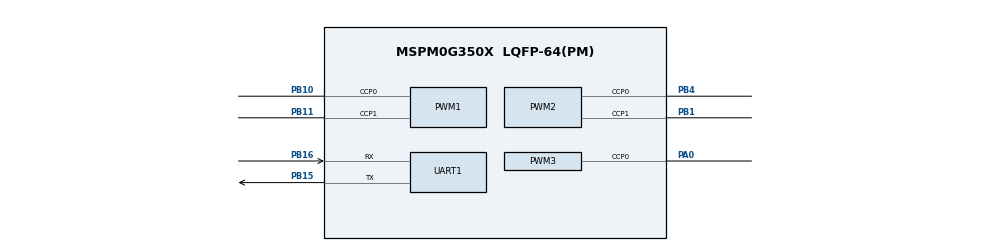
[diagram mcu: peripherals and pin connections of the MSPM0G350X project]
/**
 * @cliArgs --device "MSPM0G350X" --part "Default" --package "LQFP-64(PM)" --product "mspm0_sdk@2.11.00.07"
 * @versions {"tool":"1.26.2+4477"}
 */

/**
 * Import the modules used in this configuration.
 */
const GPIO          = scripting.addModule("/ti/driverlib/GPIO", {}, false);
const GPIO1         = GPIO.addInstance();
const PWM           = scripting.addModule("/ti/driverlib/PWM", {}, false);
const PWM1          = PWM.addInstance();
const PWM2          = PWM.addInstance();
const PWM3          = PWM.addInstance();
const SYSCTL        = scripting.addModule("/ti/driverlib/SYSCTL");
const UART          = scripting.addModule("/ti/driverlib/UART", {}, false);
const UART1         = UART.addInstance();
const ProjectConfig = scripting.addModule("/ti/project_config/ProjectConfig");

/**
 * Write custom configuration values to the imported modules.
 */
GPIO1.$name                          = "GPIO_GRP_0";
GPIO1.associatedPins[0].$name        = "PIN_0";
GPIO1.associatedPins[0].assignedPort = "PORTA";
GPIO1.associatedPins[0].ioStructure  = "SD";
GPIO1.associatedPins[0].assignedPin  = "2";

const Board = scripting.addModule("/ti/driverlib/Board", {}, false);

PWM1.$name                      = "PWM_0";
PWM1.peripheral.ccp0Pin.$assign = "PB10";
PWM1.peripheral.ccp1Pin.$assign = "PB11";
PWM1.PWM_CHANNEL_0.$name        = "ti_driverlib_pwm_PWMTimerCC0";
PWM1.PWM_CHANNEL_1.$name        = "ti_driverlib_pwm_PWMTimerCC1";
PWM1.ccp0PinConfig.$name        = "ti_driverlib_gpio_GPIOPinGeneric0";
PWM1.ccp1PinConfig.$name        = "ti_driverlib_gpio_GPIOPinGeneric1";

PWM2.$name                      = "PWM_1";
PWM2.peripheral.$assign         = "TIMA1";
PWM2.peripheral.ccp0Pin.$assign = "PB4";
PWM2.peripheral.ccp1Pin.$assign = "PB1";
PWM2.PWM_CHANNEL_0.$name        = "ti_driverlib_pwm_PWMTimerCC2";
PWM2.PWM_CHANNEL_1.$name        = "ti_driverlib_pwm_PWMTimerCC3";
PWM2.ccp0PinConfig.$name        = "ti_driverlib_gpio_GPIOPinGeneric2";
PWM2.ccp1PinConfig.$name        = "ti_driverlib_gpio_GPIOPinGeneric3";

PWM3.$name                      = "PWM_2";
PWM3.peripheral.ccp0Pin.$assign = "PA0";
PWM3.PWM_CHANNEL_0.$name        = "ti_driverlib_pwm_PWMTimerCC4";
PWM3.PWM_CHANNEL_1.$name        = "ti_driverlib_pwm_PWMTimerCC5";
PWM3.ccp0PinConfig.$name        = "ti_driverlib_gpio_GPIOPinGeneric6";
PWM3.ccp1PinConfig.$name        = "ti_driverlib_gpio_GPIOPinGeneric7";


UART1.$name                            = "UART_2";
UART1.targetBaudRate                   = 115200;
UART1.peripheral.$assign               = "UART2";
UART1.peripheral.rxPin.$assign         = "PB16";
UART1.peripheral.txPin.$assign         = "PB15";
UART1.txPinConfig.$name                = "ti_driverlib_gpio_GPIOPinGeneric4";
UART1.txPinConfig.direction            = scripting.forceWrite("OUTPUT");
UART1.txPinConfig.hideOutputInversion  = scripting.forceWrite(false);
UART1.txPinConfig.onlyInternalResistor = scripting.forceWrite(false);
UART1.txPinConfig.passedPeripheralType = scripting.forceWrite("Digital");
UART1.rxPinConfig.$name                = "ti_driverlib_gpio_GPIOPinGeneric5";
UART1.rxPinConfig.hideOutputInversion  = scripting.forceWrite(false);
UART1.rxPinConfig.onlyInternalResistor = scripting.forceWrite(false);
UART1.rxPinConfig.passedPeripheralType = scripting.forceWrite("Digital");

ProjectConfig.deviceSpin = "MSPM0G3507";

/**
 * Pinmux solution for unlocked pins/peripherals. This ensures that minor changes to the automatic solver in a future
 * version of the tool will not impact the pinmux you originally saw.  These lines can be completely deleted in order to
 * re-solve from scratch.
 */
GPIO1.associatedPins[0].pin.$suggestSolution = "PA2";
Board.peripheral.$suggestSolution            = "DEBUGSS";
Board.peripheral.swclkPin.$suggestSolution   = "PA20";
Board.peripheral.swdioPin.$suggestSolution   = "PA19";
PWM1.peripheral.$suggestSolution             = "TIMG0";
PWM3.peripheral.$suggestSolution             = "TIMA0";
PWM3.peripheral.ccp1Pin.$suggestSolution     = "PA1";
SYSCTL.peripheral.$suggestSolution           = "SYSCTL";
